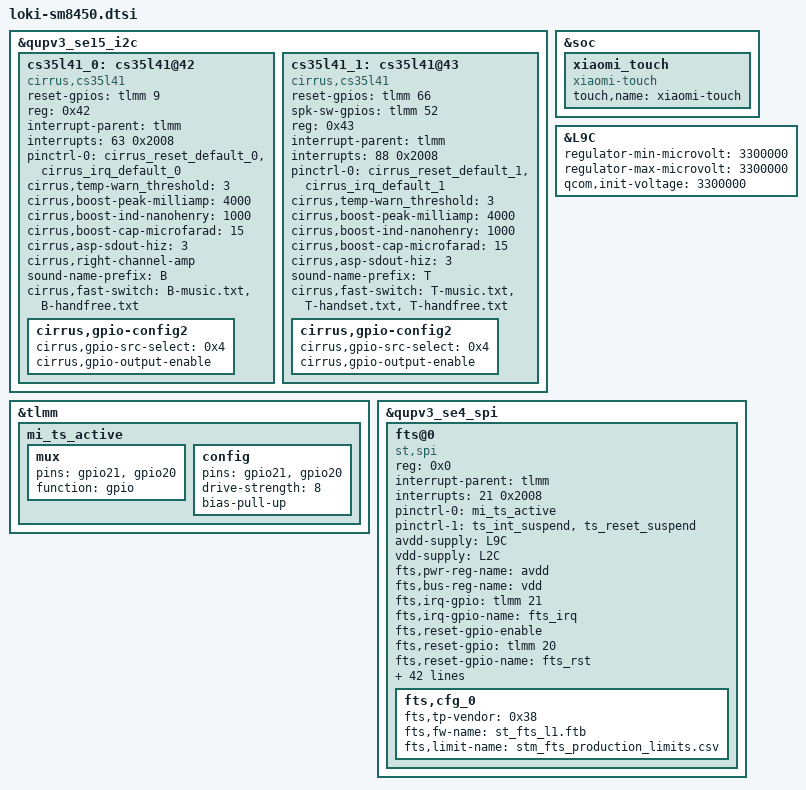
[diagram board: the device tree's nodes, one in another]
/*
   this file is for attribution only of loki
   And public attribution of xiaomi platforms
*/
#include "loki-pinctrl.dtsi"
#include "xiaomi-sm8450-common.dtsi"

&qupv3_se15_i2c {
	status = "ok";
	cs35l41_0: cs35l41@42 {
		status = "ok";
		compatible = "cirrus,cs35l41";
		reset-gpios = <&tlmm 9 0>;
		reg = <0x42>;
		interrupt-parent = <&tlmm>;
		interrupts = <63 0x2008>;
		pinctrl-names = "default";
		pinctrl-0 = <&cirrus_reset_default_0 &cirrus_irq_default_0>;
		cirrus,temp-warn_threshold = <3>;
		cirrus,boost-peak-milliamp = <4000>;
		cirrus,boost-ind-nanohenry = <1000>;
		cirrus,boost-cap-microfarad = <15>;
		cirrus,asp-sdout-hiz = <3>;
		cirrus,right-channel-amp;
		sound-name-prefix = "B";
		cirrus,fast-switch = "B-music.txt", "B-handfree.txt";
		cirrus,gpio-config2 {
			cirrus,gpio-src-select = <0x4>;
			cirrus,gpio-output-enable;
		};
	};
	cs35l41_1: cs35l41@43 {
		status = "ok";
		compatible = "cirrus,cs35l41";
		reset-gpios = <&tlmm 66 0>;
		spk-sw-gpios = <&tlmm 52 0>;
		reg = <0x43>;
		interrupt-parent = <&tlmm>;
		interrupts = <88 0x2008>;
		pinctrl-names = "default";
		pinctrl-0 = <&cirrus_reset_default_1 &cirrus_irq_default_1>;
		cirrus,temp-warn_threshold = <3>;
		cirrus,boost-peak-milliamp = <4000>;
		cirrus,boost-ind-nanohenry = <1000>;
		cirrus,boost-cap-microfarad = <15>;
		cirrus,asp-sdout-hiz = <3>;
		sound-name-prefix = "T";
		cirrus,fast-switch = "T-music.txt", "T-handset.txt", "T-handfree.txt";
		cirrus,gpio-config2 {
			cirrus,gpio-src-select = <0x4>;
			cirrus,gpio-output-enable;
		};
	};
};

&soc {
	xiaomi_touch {
		compatible = "xiaomi-touch";
		status = "ok";
		touch,name = "xiaomi-touch";
	};
};

&L9C {
	regulator-min-microvolt = <3300000>;
	regulator-max-microvolt = <3300000>;
	qcom,init-voltage = <3300000>;
};

&tlmm {
	mi_ts_active: mi_ts_active {
		mux {
				pins = "gpio21", "gpio20";
				function = "gpio";
		};

		config {
				pins = "gpio21", "gpio20";
				drive-strength = <8>;
				bias-pull-up;
		};
	};
};

&qupv3_se4_spi {
	status = "ok";
	fts@0 {
		status = "ok";
		compatible = "st,spi";
		reg = <0x0>;
		interrupt-parent = <&tlmm>;
		interrupts = <21 0x2008>;
		pinctrl-names = "pmx_ts_active", "pmx_ts_suspend";
		pinctrl-0 = <&mi_ts_active>;
		pinctrl-1 = <&ts_int_suspend &ts_reset_suspend>;
		avdd-supply = <&L9C>;
		vdd-supply = <&L2C>;
		/*panel = <&dsi_k8_42_02_0a_dsc_cmd>;*/
		fts,pwr-reg-name = "avdd";
		fts,bus-reg-name = "vdd";
		fts,irq-gpio = <&tlmm 21 0x2008>;
		fts,irq-gpio-name = "fts_irq";
		fts,reset-gpio-enable;
		fts,reset-gpio = <&tlmm 20 0x00>;
		fts,reset-gpio-name = "fts_rst";
		fts,irq-flags = <0x2008>;
		fts,x-max = <14400>;
		fts,y-max = <32000>;
		fts,fod-lx = <5860>;
		fts,fod-ly = <23460>;
		fts,fod-x-size = <2680>;
		fts,fod-y-size = <2660>;
		fts,support-fod;
/*		fts,support-thp;*/
		fts,support-thp-fw;
		spi-max-frequency = <12000000>;
		fts,support-super-resolution = <1>;
		fts,default-fw-name = "st_fts_l1.ftb";
		fts,thp-fw-name = "st_fts_l1_thp.ftb";
		fts,config-array-size = <1>;
		fts,touch-follow-performance-def = <3>;
		fts,touch-tap-sensitivity-def = <4>;
		fts,touch-aim-sensitivity-def = <3>;
		fts,touch-tap-stability-def = <3>;
		fts,cornerfilter-area-step1 = <150>;
		fts,cornerfilter-area-step2 = <280>;
		fts,cornerfilter-area-step3 = <400>;
		fts,touch-deadzone-filter-ver = <2 0 0 0 0 0 0 0
										2 1 0 0 0 0 0 0
										2 2 0 0 0 3199 0 0
										2 3 1439 0 1439 3199 0 0>;
		fts,touch-deadzone-filter-hor = <2 0 0 0 1439 7 0 0
										2 1 0 3192 1439 3199 0 0
										2 2 0 0 0 3199 0 0
										2 3 1439 0 1439 3199 0 0>;
		fts,touch-edgezone-filter-ver = <1 0 0 0 0 0 0 0
										1 1 0 0 0 0 0 0
										1 2 0 0 60 3199 0 0
										1 3 1379 0 1439 3199 0 0>;
		fts,touch-edgezone-filter-hor = <1 0 0 0 1439 70 0 0
										1 1 0 3129 1439 3199 0 0
										1 2 0 0 60 3199 0 0
										1 3 1379 0 1439 3199 0 0>;
		fts,touch-cornerzone-filter-ver = <0 0 0 0 0 0 0 0
										0 1 0 0 0 0 0 0
										0 2 0 2799 250 3199 0 0
										0 3 1189 2799 1439 3199 0 0>;
		fts,touch-cornerzone-filter-hor1 = <0 0 0 0 280 280 0 0
										0 1 0 0 0 0 0 0
										0 2 0 2919 280 3199 0 0
										0 3 0 0 0 0 0 0>;
		fts,touch-cornerzone-filter-hor2 = <0 0 0 0 0 0 0 0
										0 1 1159 0 1439 280 0 0
										0 2 0 0 0 0 0 0
										0 3 1159 2919 1439 3199 0 0>;
		fts,touch-follow-performance = <10 15 1
										8 15 1
										6 15 1
										4 15 1
										2 15 1>;
		fts,touch-tap-sensitivity = <160 150 140 120 100>;
		fts,touch-aim-sensitivity = <10 8 6 4 2>;
		fts,touch-tap-stability = <8 12 15 18 25>;
		fts,touch-expert-array = <6 15 1 120 6 15
								  2 15 1 120 4 15
								  4 15 1 120 2 15>;
		fts,cfg_0 {
			fts,tp-vendor = <0x38>;
			fts,fw-name = "st_fts_l1.ftb";
			fts,limit-name = "stm_fts_production_limits.csv";
		};
	};
};
